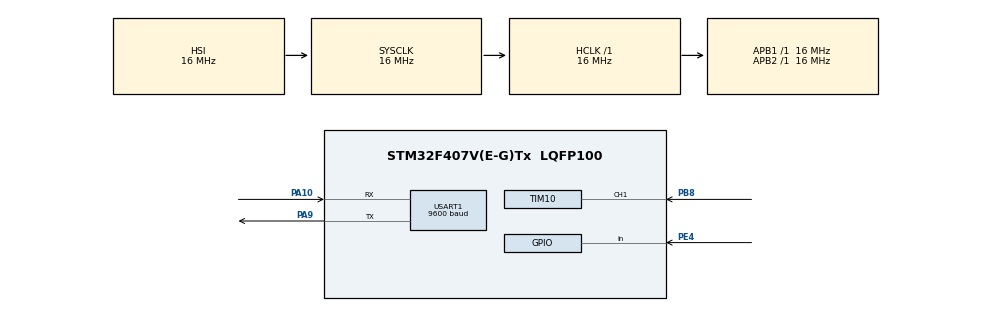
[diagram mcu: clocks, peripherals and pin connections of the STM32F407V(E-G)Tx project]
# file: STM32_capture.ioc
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Mcu.Family=STM32F4
Mcu.Name=STM32F407V(E-G)Tx
Mcu.Package=LQFP100
NVIC.PriorityGroup=NVIC_PRIORITYGROUP_4
PA10.Mode=Asynchronous
PA10.Signal=USART1_RX
PA13.Mode=Serial_Wire
PA13.Signal=SYS_JTMS-SWDIO
PA14.Mode=Serial_Wire
PA14.Signal=SYS_JTCK-SWCLK
PA9.Mode=Asynchronous
PA9.Signal=USART1_TX
PB8.GPIO_PuPd=GPIO_PULLDOWN
PB8.Signal=S_TIM10_CH1
PE4.GPIO_PuPd=GPIO_PULLUP
PE4.Signal=GPIO_Input
PH0-OSC_IN.Mode=HSE-External-Oscillator
PH0-OSC_IN.Signal=RCC_OSC_IN
PH1-OSC_OUT.Mode=HSE-External-Oscillator
PH1-OSC_OUT.Signal=RCC_OSC_OUT
ProjectManager.HeapSize=0x200
ProjectManager.StackSize=0x400
ProjectManager.TargetToolchain=STM32CubeIDE
RCC.AHBFreq_Value=16000000
RCC.APB1Freq_Value=16000000
RCC.APB2Freq_Value=16000000
RCC.CortexFreq_Value=16000000
RCC.HSE_VALUE=25000000
RCC.HSI_VALUE=16000000
RCC.LSE_VALUE=32768
RCC.SYSCLKFreq_VALUE=16000000
RCC.VCOOutputFreq_Value=192000000
SH.S_TIM10_CH1.0=TIM10_CH1,Input_Capture1_from_TI1
TIM10.AutoReloadPreload=TIM_AUTORELOAD_PRELOAD_ENABLE
TIM10.Channel=TIM_CHANNEL_1
TIM10.Prescaler=15999
USART1.BaudRate=9600
USART1.VirtualMode=VM_ASYNC
VP_TIM10_VS_ClockSourceINT.Mode=Enable_Timer
board=custom

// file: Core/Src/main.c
/* USER CODE BEGIN Header */
/**
  ******************************************************************************
  * @file           : main.c
  * @brief          : Main program body
  ******************************************************************************
  * @attention
  *
  * Copyright (c) 2025 STMicroelectronics.
  * All rights reserved.
  *
  * This software is licensed under terms that can be found in the LICENSE file
  * in the root directory of this software component.
  * If no LICENSE file comes with this software, it is provided AS-IS.
  *
  ******************************************************************************
  */
/* USER CODE END Header */
#include "main.h"

/* USER CODE BEGIN Includes */
#include<string.h>
#include<stdio.h>
/* USER CODE END Includes */

TIM_HandleTypeDef htim10;

UART_HandleTypeDef huart1;

void SystemClock_Config(void);
static void MX_GPIO_Init(void);
static void MX_TIM10_Init(void);
static void MX_USART1_UART_Init(void);

int main(void)
{

  /* MCU Configuration--------------------------------------------------------*/

  /* Reset of all peripherals, Initializes the Flash interface and the Systick. */
  HAL_Init();

  /* Configure the system clock */
  SystemClock_Config();

  /* Initialize all configured peripherals */
  MX_GPIO_Init();
  MX_TIM10_Init();
  MX_USART1_UART_Init();
  /* USER CODE BEGIN 2 */
  HAL_TIM_IC_Init(&htim10);
  HAL_TIM_IC_Start(&htim10, TIM_CHANNEL_1);
  int a;
  char b[10];

  /* USER CODE END 2 */

  /* Infinite loop */
  while (1)
  {

    /* USER CODE BEGIN 3 */
	  if(__HAL_TIM_GET_FLAG(&htim10,TIM_FLAG_CC1)==SET){
	  		  a=HAL_TIM_ReadCapturedValue(&htim10,TIM_CHANNEL_1 );
	  		  sprintf(b,"%d\r\n",a);
	  		  HAL_UART_Transmit(&huart1, b,strlen(b) , 100);
	  		  __HAL_TIM_CLEAR_FLAG(&htim10,TIM_FLAG_CC1);
	  	  }

  }
  /* USER CODE END 3 */
}

void SystemClock_Config(void)
{
  RCC_OscInitTypeDef RCC_OscInitStruct = {0};
  RCC_ClkInitTypeDef RCC_ClkInitStruct = {0};

  /** Configure the main internal regulator output voltage
  */
  __HAL_RCC_PWR_CLK_ENABLE();
  __HAL_PWR_VOLTAGESCALING_CONFIG(PWR_REGULATOR_VOLTAGE_SCALE1);

  /** Initializes the RCC Oscillators according to the specified parameters
  * in the RCC_OscInitTypeDef structure.
  */
  RCC_OscInitStruct.OscillatorType = RCC_OSCILLATORTYPE_HSI;
  RCC_OscInitStruct.HSIState = RCC_HSI_ON;
  RCC_OscInitStruct.HSICalibrationValue = RCC_HSICALIBRATION_DEFAULT;
  RCC_OscInitStruct.PLL.PLLState = RCC_PLL_NONE;
  if (HAL_RCC_OscConfig(&RCC_OscInitStruct) != HAL_OK)
  {
    Error_Handler();
  }

  /** Initializes the CPU, AHB and APB buses clocks
  */
  RCC_ClkInitStruct.ClockType = RCC_CLOCKTYPE_HCLK|RCC_CLOCKTYPE_SYSCLK
                              |RCC_CLOCKTYPE_PCLK1|RCC_CLOCKTYPE_PCLK2;
  RCC_ClkInitStruct.SYSCLKSource = RCC_SYSCLKSOURCE_HSI;
  RCC_ClkInitStruct.AHBCLKDivider = RCC_SYSCLK_DIV1;
  RCC_ClkInitStruct.APB1CLKDivider = RCC_HCLK_DIV1;
  RCC_ClkInitStruct.APB2CLKDivider = RCC_HCLK_DIV1;

  if (HAL_RCC_ClockConfig(&RCC_ClkInitStruct, FLASH_LATENCY_0) != HAL_OK)
  {
    Error_Handler();
  }
}

static void MX_TIM10_Init(void)
{

  TIM_IC_InitTypeDef sConfigIC = {0};

  htim10.Instance = TIM10;
  htim10.Init.Prescaler = 15999;
  htim10.Init.CounterMode = TIM_COUNTERMODE_UP;
  htim10.Init.Period = 65535;
  htim10.Init.ClockDivision = TIM_CLOCKDIVISION_DIV1;
  htim10.Init.AutoReloadPreload = TIM_AUTORELOAD_PRELOAD_ENABLE;
  if (HAL_TIM_Base_Init(&htim10) != HAL_OK)
  {
    Error_Handler();
  }
  if (HAL_TIM_IC_Init(&htim10) != HAL_OK)
  {
    Error_Handler();
  }
  sConfigIC.ICPolarity = TIM_INPUTCHANNELPOLARITY_RISING;
  sConfigIC.ICSelection = TIM_ICSELECTION_DIRECTTI;
  sConfigIC.ICPrescaler = TIM_ICPSC_DIV1;
  sConfigIC.ICFilter = 0;
  if (HAL_TIM_IC_ConfigChannel(&htim10, &sConfigIC, TIM_CHANNEL_1) != HAL_OK)
  {
    Error_Handler();
  }

}

static void MX_USART1_UART_Init(void)
{

  huart1.Instance = USART1;
  huart1.Init.BaudRate = 9600;
  huart1.Init.WordLength = UART_WORDLENGTH_8B;
  huart1.Init.StopBits = UART_STOPBITS_1;
  huart1.Init.Parity = UART_PARITY_NONE;
  huart1.Init.Mode = UART_MODE_TX_RX;
  huart1.Init.HwFlowCtl = UART_HWCONTROL_NONE;
  huart1.Init.OverSampling = UART_OVERSAMPLING_16;
  if (HAL_UART_Init(&huart1) != HAL_OK)
  {
    Error_Handler();
  }

}

static void MX_GPIO_Init(void)
{
  GPIO_InitTypeDef GPIO_InitStruct = {0};

  /* GPIO Ports Clock Enable */
  __HAL_RCC_GPIOE_CLK_ENABLE();
  __HAL_RCC_GPIOH_CLK_ENABLE();
  __HAL_RCC_GPIOA_CLK_ENABLE();
  __HAL_RCC_GPIOB_CLK_ENABLE();

  /*Configure GPIO pin : PE4 */
  GPIO_InitStruct.Pin = GPIO_PIN_4;
  GPIO_InitStruct.Mode = GPIO_MODE_INPUT;
  GPIO_InitStruct.Pull = GPIO_PULLUP;
  HAL_GPIO_Init(GPIOE, &GPIO_InitStruct);

}

void Error_Handler(void)
{
  __disable_irq();
  while (1)
  {
  }
}
